# ADuCM410 register map
Vendor: Analog Devices; Series: ADuCM410; File version: 1p0
CPU: CM33 r0p1, little endian, MPU, FPU, 3 interrupt priority bits
Registers are 32-bit, read-write, reset 0x0 unless marked. A register's access mark holds for its fields unless they carry their own. Offsets are from the block's base; [hi:lo] are bit positions; {n}, {i} and the like mark numbered series.

## GPIO
Base 0x40050000
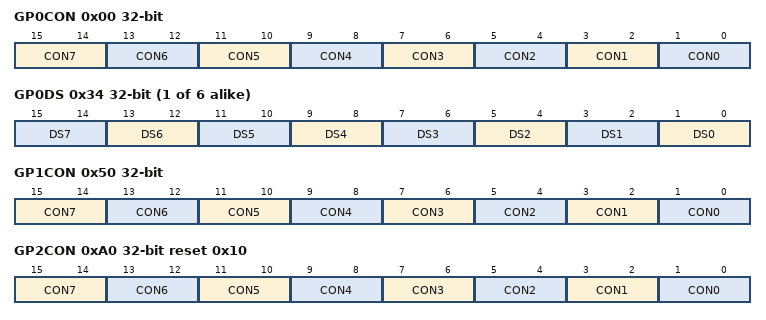
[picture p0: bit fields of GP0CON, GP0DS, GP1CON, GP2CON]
0x00 GP0CON — GPIO Port 0 Configuration
  [15:14] CON7 — P0.7 Configuration Bits
    0=GPIO; 1=SDA2 (I2C2 SDA); 2=COMPDIN1 (Comparator Data Input 1); 3=PLAO5
  [13:12] CON6 — P0.6 Configuration Bits
    0=GPIO; 1=SCL2 (I2C2 SCL); 2=COMPDIN0 (Comparator Data Input 0); 3=PLAO4
  [11:10] CON5 — P0.5 Configuration Bits
    0=GPIO; 1=SDA0 (I2C0 SDA); 2=SOUT0 (UART0 SOUT); 3=PLAO3
  [9:8] CON4 — P0.4 Configuration Bits
    0=GPIO; 1=SCL0 (I2C0 SCL); 2=SIN0 (UART0 SIN); 3=PLAO2
  [7:6] CON3 — P0.3 Configuration Bits
    0=GPIOIRQ0; 1=CS0 (SPI0 CS); 2=PLACLK0; 3=PLAI3
  [5:4] CON2 — P0.2 Configuration Bits
    0=GPIO; 1=MOSI0 (SPI0 MOSI); 2=PLACLK1 (PLA Clock 1); 3=PLAI2
  [3:2] CON1 — P0.1 Configuration Bits
    0=GPIO; 1=MISO0 (SPI0 MISO); 2=COMOUT1 (Comparater Output); 3=PLAI1
  [1:0] CON0 — P0.0 Configuration Bits
    0=GPIO; 1=SCLK0 (SPI0 SCLK); 2=COMOUT0 (Comparater Output); 3=PLAI0
0x04 GP0OE — GPIO Port 0 Output Enable
  [7:0] OE range 0x00000000..0x000000FF — Open Drain Enable
{0x8+0x50*i} GP{i}IE (i=0..5) — GPIO Port {i} Input Path Enable
  [7:0] IE range 0x00000000..0x000000FF — Input Enable
{0xC+0x50*i} GP{i}IN (i=0..5) — GPIO Port {i} Registered Data Input
  [7:0] Y ro — Data Input from Pad
{0x10+0x50*i} GP{i}OUT (i=0..5) — GPIO Port {i} Data Output
  [7:0] A range 0x00000000..0x000000FF — Data Output to Pad
{0x14+0x50*i} GP{i}SET (i=0..5) — GPIO Port {i} Data Out Set
  [7:0] SETUP wo range 0x00000000..0x000000FF — Set the Output HIGH for the Pin
{0x18+0x50*i} GP{i}CLR (i=0..5) — GPIO Port {i} Data Out Clear
  [7:0] CLR wo range 0x00000000..0x000000FF — Set the Output Low for the Port Pin
{0x1C+0x50*i} GP{i}TGL (i=0..5) — GPIO Port {i} Pin Toggle
  [7:0] TGL wo range 0x00000000..0x000000FF — Toggle the Output of the Port Pin
{0x20+0x50*i} GP{i}ODE (i=0..5) — GPIO Port {i} Open Drain Enable
  [7:0] ODE range 0x00000000..0x000000FF — Open Drain Enable
{0x24+0x50*i} GP{i}IS reset 0xFF (i=0..5) — GPIO Port {i} Input Select
  [7:0] ISEL range 0x00000000..0x000000FF — Input Select
{0x28+0x50*i} GP{i}PE (i=0..5) — GPIO Port {i} Pull Enable
  [7:0] PE range 0x00000000..0x000000FF — Pull Enable
{0x2C+0x50*i} GP{i}PS reset 0xFF (i=0..5) — GPIO Port {i} Pull Select
  [7:0] PS range 0x00000000..0x000000FF — Pull Select
{0x30+0x50*i} GP{i}SR (i=0..5) — GPIO Port {i} Slew Rate
  [7:0] SR range 0x00000000..0x000000FF — Slew Rate
{0x34+0x50*i} GP{i}DS (i=0..5) — GPIO Port {i} Drive Select
  [all] fields
    {v}=STRENGTH{v+1} (Drive Strength {v+1}) (v=0..3)
  [2n+1:2n] DS{n} (n=0..7) — Drive Select
0x38 GP0PWR reset 0xF — GPIO Port 0 Power Select
  [3:0] PWR range 0x00000000..0x0000000F — Pad Power Select
0x3C GP0POL — GPIO Interrupt Polarity Select
  [7:0] INTPOL range 0x00000000..0x000000FF — Parametric Output
{0x40+0x50*i} GP{i}IENA (i=0..5) — InterruptA Enable
  [7:0] INTAEN range 0x00000000..0x000000FF
0x44 GP0IENB — InterruptB Enable
  [7:0] INTBEN range 0x00000000..0x000000FF — InterruptA Enable
{0x48+0x50*i} GP{i}INT (i=0..5) — Interrupt Status
  [7:0] INTSTATUS range 0x00000000..0x000000FF
0x50 GP1CON — GPIO Port 1 Configuration
  [15:14] CON7 — P1.7 Configuration Bits
    0=GPIO (GPIO/IRQ1); 1=CS1 (SPI1 CS); 2=PWM5; 3=PLAO13
  [13:12] CON6 — P1.6 Configuration Bits
    0=GPIO; 1=MOSI1 (SPI1 MOSI); 2=PWM4; 3=PLAO12
  [11:10] CON5 — P1.5 Configuration Bits
    0=GPIO; 1=MISO1 (SPI1 MISO); 2=PWM3; 3=PLAO11
  [9:8] CON4 — P1.4 Configuration Bits
    0=GPIO; 1=SCLK1 (SPI1 SCLK); 2=PWM2; 3=PLAO10
  [7:6] CON3 — P1.3 Configuration Bits
    0=GPIO; 1=SDA1 (I2C1 SDA); 2=PWM1; 3=PLAI7
  [5:4] CON2 — P1.2 Configuration Bits
    0=GPIO; 1=SCL1 (I2C1 SCL); 2=PWM0; 3=PLAI6
  [3:2] CON1 — P1.1 Configuration Bits
    0=GPIO; 1=SOUT1 (UART 1 SOUT); 2=COMDOUT3 (Comparater Output 3); 3=PLAI5
  [1:0] CON0 — P1.0 Configuration Bits
    0=GPIO; 1=SIN1 (UART1 SIN); 2=COMPOUT2 (Comparater Output 2); 3=PLAI4
0x54 GP1OE — GPIO Port 1 Output Enable
  [7:0] OE range 0x00000000..0x000000FF — Output Enable
0x88 GP1PWR reset 0xFF — GPIO Port 1 Power Select
  [7:0] PWR range 0x00000000..0x000000FF — Pad Power Select
0x8C GP1POL — GPIO Interrupt Polarity Select
  [7:0] INTPOL range 0x00000000..0x000000FF — Parametric Output
{0x44+0x50*i} GP{i}IENB (i=1..5) — InterruptB Enable
  [7:0] INTBEN range 0x00000000..0x000000FF
0xA0 GP2CON reset 0x10 — GPIO Port 2 Configuration
  [15:14] CON7 — P2.7 Configuration Bits
    0=GPIOIRQ6; 1=CS2 (SPI 2 CS); 2=SDA1 (I2C1 SDA of ITLA package); 3=PLAO21
  [13:12] CON6 — P2.6 Configuration Bits
    0=GPIOIRQ5; 1=SCLK2 (SPI 2 SCLK); 2=SCL1 (I2C1 SCL of ITLA Package); 3=PLAO20
  [11:10] CON5 — P2.5 Configuration Bits
    0=GPIO; 1=MISO2 (Spi2 Miso); 2=SOUT1 (UART1 TX of ITLA package); 3=PLAO19
  [9:8] CON4 — P2.4 Configuration Bits
    0=GIPO (GPIO/IRQ4); 1=MOSI2 (SPI2 MOSI); 2=SIN1 (UART1 RX of ITLA package); 3=PLAO18
  [7:6] CON3 — P2.3 Configuration Bits
    0=GPIOBM; 3=PLAI10
  [5:4] CON2 — P2.2 Configuration Bits
    0=GPIO; 1=POR (Power Reset); 2=CLKOUT (Clock Output); 3=SWO (Serial Wire Output)
  [3:2] CON1 — P2.1 Configuration Bits
    0=GPIOIRQ2; 1=ECLKIN (External Clock in); 2=COMPDIN3 (Comparater Data Input); 3=PLAI9
  [1:0] CON0 — P2.0 Configuration Bits
    0=GPIO; 1=ADCCONV (ADC Convert); 2=COMDIN2 (Comparator Data Input 2); 3=PLAI8 (PLA GPIO Input[8])
0xA4 GP2OE reset 0x4 — GPIO Port 2 Output Enable
  [7:0] OE range 0x00000000..0x000000FF — Output Enable
0xDC GP2POL — Interrupt Polarity
  [7:0] INTPOL range 0x00000000..0x000000FF
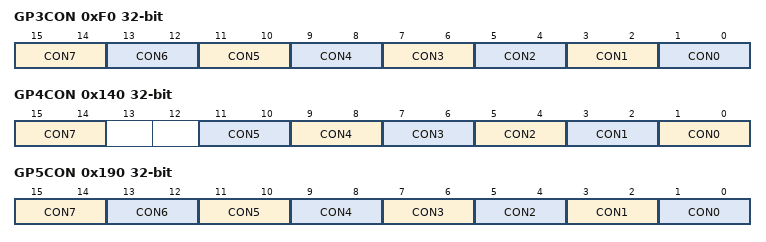
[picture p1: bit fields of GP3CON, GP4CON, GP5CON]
0xF0 GP3CON — GPIO Port 3 Configuration
  [15:14] CON7 — P3.7 Configuration Bits
    0=GPIO; 3=PLAO29
  [13:12] CON6 — P3.6 Configuration Bits
    0=GPIO; 1=MDIO (SLAVE MDIO MDIO); 2=SRDY2 (SPI 2 Sready); 3=PLAO30 (PLA Output 30)
  [11:10] CON5 — P3.5 Configuration Bits
    0=GPIO; 1=MCK (SLVA MDIO MCK); 2=SRDY1 (SPI 1 Sready); 3=PLAO27
  [9:8] CON4 — P3.4 Configuration Bits
    0=GPIOIRQ9; 1=PRTADDR4 (MDIO Port Address 4); 2=SOUT0 (Duplicate SOUT0); 3=PLAO26
  [7:6] CON3 — P3.3 Configuration Bits
    0=GPIO; 1=PRTADDR3 (MDIO Port Address3); 2=SIN0 (Duplicate SIN0); 3=PLAI15
  [5:4] CON2 — P3.2 Configuration Bits
    0=GPIO; 1=PRTADD2 (MDIO Port Address2); 2=PWMTRIP; 3=PLAI14
  [3:2] CON1 — P3.1 Configuration Bits
    0=GPIO; 1=PRTADDR1 (MDIO PRTADDR1); 2=PWMSYNC; 3=PLAI13
  [1:0] CON0 — P3.0 Configuration Bits
    0=GPIO (GPIO/IRQ8); 1=PRTADDR0 (MDIO Port Address 0); 2=SRDY0 (SPI 0 Sready); 3=PLAI12
{0x4+0x50*i} GP{i}OE (i=3..5) — GPIO Port {i} Output Enable
  [7:0] OE range 0x00000000..0x000000FF — Output Enable
{0x3C+0x50*i} GP{i}POL (i=3..5) — GPIO Interrupt Polarity Select
  [7:0] INTPOL range 0x00000000..0x000000FF — Parametric Output
0x140 GP4CON — GPIO Port 4 Configuration
  [15:14] CON7 — P4.7 Configuration Bits
    0=GPIOIRQ7; 2=PLACLK2 (PLA Clock 2)
  [11:10] CON5 — P4.5 Configuration Bits
    0=GPIO
  [9:8] CON4 — P4.4 Configuration Bits
    0=GPIO; 1=VDAC5
  [7:6] CON3 — P4.3 Configuration Bits
    0=GPIO
  [5:4] CON2 — P4.2 Configuration Bits
    0=GPIO; 1=VDAC7
  [3:2] CON1 — P4.1 Configuration Bits
    0=GPIO; 1=VDAC6; 3=PLAO28
  [1:0] CON0 — P4.0 Configuration Bits
    0=GPIO; 1=VDAC3; 3=PLAI11
0x190 GP5CON — GPIO Port 6 Configuration
  [15:14] CON7 — P5.7 Configuration Bits
    0=GPIO (GPIO/IRQ_HV); 1=full_mux6
  [13:12] CON6 — P5.6 Configuration Bits
    0=GPIO (GPIO/IRQ_HV); 1=full_mux6
  [11:10] CON5 — P5.5 Configuration Bits
    0=GPIO; 1=full_mux5
  [9:8] CON4 — P5.4 Configuration Bits
    0=GPIO; 1=full_mux4
  [7:6] CON3 — P5.3 Configuration Bits
    0=GPIO; 1=full_mux3; 2=VDAC11
  [5:4] CON2 — P5.2 Configuration Bits
    0=GPIO; 1=full_mux2; 2=VDAC10
  [3:2] CON1 — P5.1 Configuration Bits
    0=GPIO; 1=full_mux1; 2=VDAC9
  [1:0] CON0 — P5.0 Configuration Bits
    0=GPIO; 1=full_mux0; 2=VDAC8
